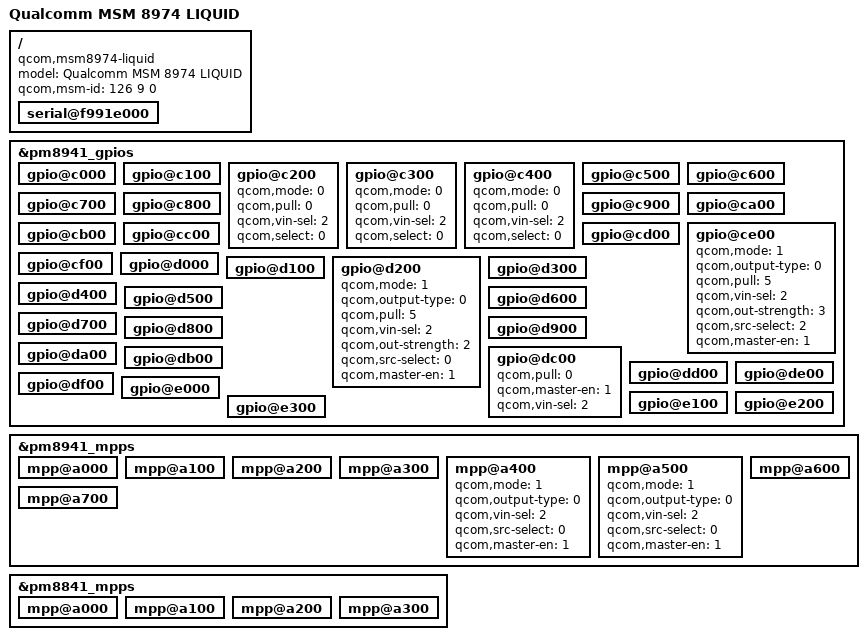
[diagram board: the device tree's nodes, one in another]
/* Copyright (c) 2012, The Linux Foundation. All rights reserved.
 *
 * This program is free software; you can redistribute it and/or modify
 * it under the terms of the GNU General Public License version 2 and
 * only version 2 as published by the Free Software Foundation.
 *
 * This program is distributed in the hope that it will be useful,
 * but WITHOUT ANY WARRANTY; without even the implied warranty of
 * MERCHANTABILITY or FITNESS FOR A PARTICULAR PURPOSE.  See the
 * GNU General Public License for more details.
 */

/dts-v1/;

/include/ "msm8974.dtsi"

/ {
	model = "Qualcomm MSM 8974 LIQUID";
	compatible = "qcom,msm8974-liquid", "qcom,msm8974";
	qcom,msm-id = <126 9 0>;

	serial@f991e000 {
		status = "ok";
	};
};

&pm8941_gpios {
	gpio@c000 { /* GPIO 1 */
	};

	gpio@c100 { /* GPIO 2 */
	};

	gpio@c200 { /* GPIO 3 */
		qcom,mode = <0>;
		qcom,pull = <0>;
		qcom,vin-sel = <2>;
		qcom,select = <0>;
	};

	gpio@c300 { /* GPIO 4 */
		qcom,mode = <0>;
		qcom,pull = <0>;
		qcom,vin-sel = <2>;
		qcom,select = <0>;
	};

	gpio@c400 { /* GPIO 5 */
		qcom,mode = <0>;
		qcom,pull = <0>;
		qcom,vin-sel = <2>;
		qcom,select = <0>;
	};

	gpio@c500 { /* GPIO 6 */
	};

	gpio@c600 { /* GPIO 7 */
	};

	gpio@c700 { /* GPIO 8 */
	};

	gpio@c800 { /* GPIO 9 */
	};

	gpio@c900 { /* GPIO 10 */
	};

	gpio@ca00 { /* GPIO 11 */
	};

	gpio@cb00 { /* GPIO 12 */
	};

	gpio@cc00 { /* GPIO 13 */
	};

	gpio@cd00 { /* GPIO 14 */
	};

	gpio@ce00 { /* GPIO 15 */
		qcom,mode = <1>;
		qcom,output-type = <0>;
		qcom,pull = <5>;
		qcom,vin-sel = <2>;
		qcom,out-strength = <3>;
		qcom,src-select = <2>;
		qcom,master-en = <1>;
	};

	gpio@cf00 { /* GPIO 16 */
	};

	gpio@d000 { /* GPIO 17 */
	};

	gpio@d100 { /* GPIO 18 */
	};

	gpio@d200 { /* GPIO 19 */
		qcom,mode = <1>;		/* QPNP_PIN_MODE_DIG_OUT */
		qcom,output-type = <0>;		/* QPNP_PIN_OUT_BUF_CMOS */
		qcom,pull = <5>;		/* QPNP_PIN_PULL_NO */
		qcom,vin-sel = <2>;		/* QPNP_PIN_VIN2 */
		qcom,out-strength = <2>;	/* QPNP_PIN_OUT_STRENGTH_MED */
		qcom,src-select = <0>;		/* QPNP_PIN_SEL_FUNC_CONSTANT */
		qcom,master-en = <1>;
	};

	gpio@d300 { /* GPIO 20 */
	};

	gpio@d400 { /* GPIO 21 */
	};

	gpio@d500 { /* GPIO 22 */
	};

	gpio@d600 { /* GPIO 23 */
	};

	gpio@d700 { /* GPIO 24 */
	};

	gpio@d800 { /* GPIO 25 */
	};

	gpio@d900 { /* GPIO 26 */
	};

	gpio@da00 { /* GPIO 27 */
	};

	gpio@db00 { /* GPIO 28 */
	};

	gpio@dc00 { /* GPIO 29 */
		qcom,pull = <0>; /* set to default pull */
		qcom,master-en = <1>;
		qcom,vin-sel = <2>; /* select 1.8 V source */
	};

	gpio@dd00 { /* GPIO 30 */
	};

	gpio@de00 { /* GPIO 31 */
	};

	gpio@df00 { /* GPIO 32 */
	};

	gpio@e000 { /* GPIO 33 */
	};

	gpio@e100 { /* GPIO 34 */
	};

	gpio@e200 { /* GPIO 35 */
	};

	gpio@e300 { /* GPIO 36 */
	};
};

&pm8941_mpps {

	mpp@a000 { /* MPP 1 */
	};

	mpp@a100 { /* MPP 2 */
	};

	mpp@a200 { /* MPP 3 */
	};

	mpp@a300 { /* MPP 4 */
	};

	mpp@a400 { /* MPP 5 */
		/* SPI_ETH config */
		qcom,mode = <1>; /* DIG_OUT */
		qcom,output-type = <0>; /* CMOS */
		qcom,vin-sel = <2>; /* PM8941_S3 1.8V > 1.6V */
		qcom,src-select = <0>; /* CONSTANT */
		qcom,master-en = <1>; /* ENABLE MPP */
	};

	mpp@a500 { /* MPP 6 */
		/* SPI_ETH_RST config */
		qcom,mode = <1>; /* DIG_OUT */
		qcom,output-type = <0>; /* CMOS */
		qcom,vin-sel = <2>; /* PM8941_S3 1.8V > 1.6V */
		qcom,src-select = <0>; /* CONSTANT */
		qcom,master-en = <1>; /* ENABLE MPP */
	};

	mpp@a600 { /* MPP 7 */
	};

	mpp@a700 { /* MPP 8 */
	};
};

&pm8841_mpps {

	mpp@a000 { /* MPP 1 */
	};

	mpp@a100 { /* MPP 2 */
	};

	mpp@a200 { /* MPP 3 */
	};

	mpp@a300 { /* MPP 4 */
	};
};
